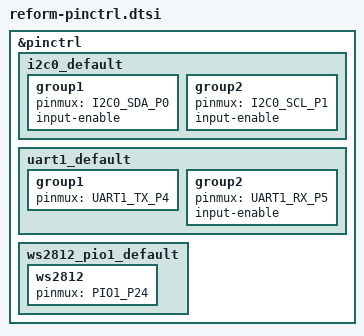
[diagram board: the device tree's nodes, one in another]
#include <zephyr/dt-bindings/pinctrl/rpi-pico-rp2040-pinctrl.h>


&pinctrl {
    i2c0_default: i2c0_default {
        group1 {
            pinmux = <I2C0_SDA_P0>;
            input-enable;
        };
        group2 {
            pinmux = <I2C0_SCL_P1>;
            input-enable;
        };
    };

    uart1_default: uart1_default {
        group1 {
            pinmux = <UART1_TX_P4>;
        };
        group2 {
            pinmux = <UART1_RX_P5>;
            input-enable;
        };
    };

    ws2812_pio1_default: ws2812_pio1_default {
        ws2812 {
            pinmux = <PIO1_P24>;
        };
    };
};
